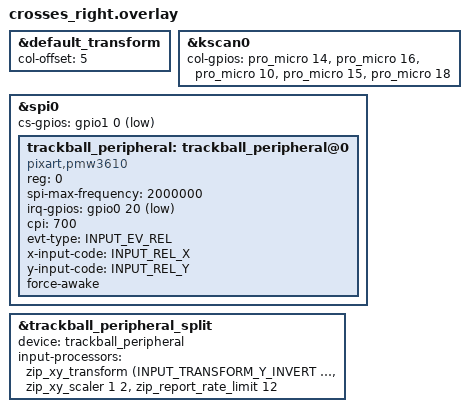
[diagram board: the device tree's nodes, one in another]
#include "crosses.dtsi"
#include <zephyr/dt-bindings/input/input-event-codes.h>
#include <input/processors/report_rate_limit.dtsi>

&default_transform {
  col-offset = <5>;
};

&kscan0 {
  col-gpios
    = <&pro_micro 14 GPIO_ACTIVE_HIGH>
    , <&pro_micro 16 GPIO_ACTIVE_HIGH>
    , <&pro_micro 10 GPIO_ACTIVE_HIGH>
    , <&pro_micro 15 GPIO_ACTIVE_HIGH>
    , <&pro_micro 18 GPIO_ACTIVE_HIGH>
    ;
};

&spi0 {
  cs-gpios = <&gpio1 0 GPIO_ACTIVE_LOW>;

  trackball_peripheral: trackball_peripheral@0 {
    status = "okay";
    compatible = "pixart,pmw3610";
    reg = <0>;
    spi-max-frequency = <2000000>;
    irq-gpios = <&gpio0 20 (GPIO_ACTIVE_LOW | GPIO_PULL_UP)>;
    cpi = <700>;
    evt-type = <INPUT_EV_REL>;
    x-input-code = <INPUT_REL_X>;
    y-input-code = <INPUT_REL_Y>;
    force-awake;
    /* keep the sensor awake while ZMK activity state is ACTIVE,
        fallback to normal downshift mode after ZMK goes into IDLE / SLEEP mode.
        thus, the sensor would be a `wakeup-source` */
  };
};

// Overrides for the input-split child node
&trackball_peripheral_split {
  device = <&trackball_peripheral>;
  input-processors
    = <&zip_xy_transform (INPUT_TRANSFORM_Y_INVERT | INPUT_TRANSFORM_X_INVERT | INPUT_TRANSFORM_XY_SWAP)>
    , <&zip_xy_scaler 1 2>
    , <&zip_report_rate_limit 12>
    ;
};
